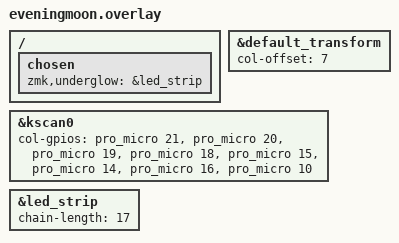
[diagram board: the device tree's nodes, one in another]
/*
 * Copyright (c) 2020 Pete Johanson
 *
 * SPDX-License-Identifier: MIT
 */

#include "endless.dtsi"

#include <behaviors.dtsi>
#include <dt-bindings/zmk/keys.h>
#include <dt-bindings/zmk/bt.h>
#include <dt-bindings/zmk/rgb.h>
#include <dt-bindings/led/led.h>

/ {
	chosen {
		zmk,underglow = &led_strip;
	};
};

&default_transform {
	col-offset = <7>;
};

&kscan0 {
    col-gpios
        = <&pro_micro 21 GPIO_ACTIVE_HIGH>
        , <&pro_micro 20 GPIO_ACTIVE_HIGH>
        , <&pro_micro 19 GPIO_ACTIVE_HIGH>
        , <&pro_micro 18 GPIO_ACTIVE_HIGH>
        , <&pro_micro 15 GPIO_ACTIVE_HIGH>
        , <&pro_micro 14 GPIO_ACTIVE_HIGH>
        , <&pro_micro 16 GPIO_ACTIVE_HIGH>
        , <&pro_micro 10 GPIO_ACTIVE_HIGH>
        ;
};

&led_strip {
    chain-length = <17>;
};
